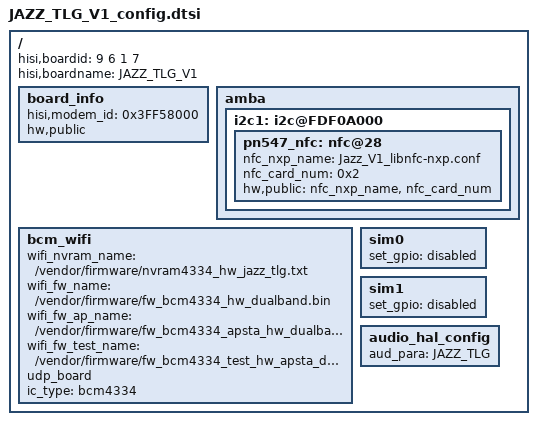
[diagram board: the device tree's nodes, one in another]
/*
 * Hisilicon Ltd.
 *
 * A15x4 A7x4
 *
 * It is only a demo for hisilicon hi3630 board. You show change the
 * address of each node according to datasheet.
 */


/include/ "hisi_sim_hotplug.dtsi"
/include/ "JAZZ_ULG_V1_config.dtsi"

/ {
	hisi,boardid = <9 6 1 7>;
	hisi,boardname = "JAZZ_TLG_V1";
	board_info: board_info {
		hisi,modem_id = <0x3FF58000>;
		hw,public;
	};
	amba {
		i2c1: i2c@FDF0A000 {
			pn547_nfc:nfc@28 {
					  nfc_nxp_name = "Jazz_V1_libnfc-nxp.conf";
					  nfc_card_num = <0x2>;
					  hw,public="nfc_nxp_name","nfc_card_num";
			};
		};
	};
	bcm_wifi {
		wifi_nvram_name = "/vendor/firmware/nvram4334_hw_jazz_tlg.txt";
		wifi_fw_name = "/vendor/firmware/fw_bcm4334_hw_dualband.bin";
		wifi_fw_ap_name = "/vendor/firmware/fw_bcm4334_apsta_hw_dualband.bin";
		wifi_fw_test_name = "/vendor/firmware/fw_bcm4334_test_hw_apsta_dualband.bin";
		udp_board;
		ic_type= "bcm4334";
		status = "ok";
	};
	sim0 {
		status = "ok";
		set_gpio="disabled";
	};
	sim1 {
		status = "ok";
		set_gpio="disabled";
	};
	audio_hal_config {
		aud_para = "JAZZ_TLG";
	};
};
